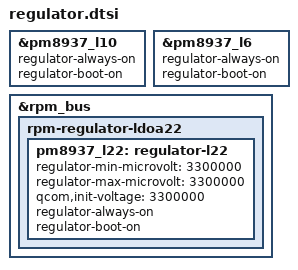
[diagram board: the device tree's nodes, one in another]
&pm8937_l10 {
	regulator-always-on;
	regulator-boot-on;
};

&pm8937_l6 {
	regulator-always-on;
	regulator-boot-on;
};

&rpm_bus {
	rpm-regulator-ldoa22 {
		status = "okay";
		pm8937_l22: regulator-l22 {
			regulator-min-microvolt = <3300000>;
			regulator-max-microvolt = <3300000>;
			qcom,init-voltage = <3300000>;
			regulator-always-on;
			regulator-boot-on;
			status = "okay";
		};
	};
};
